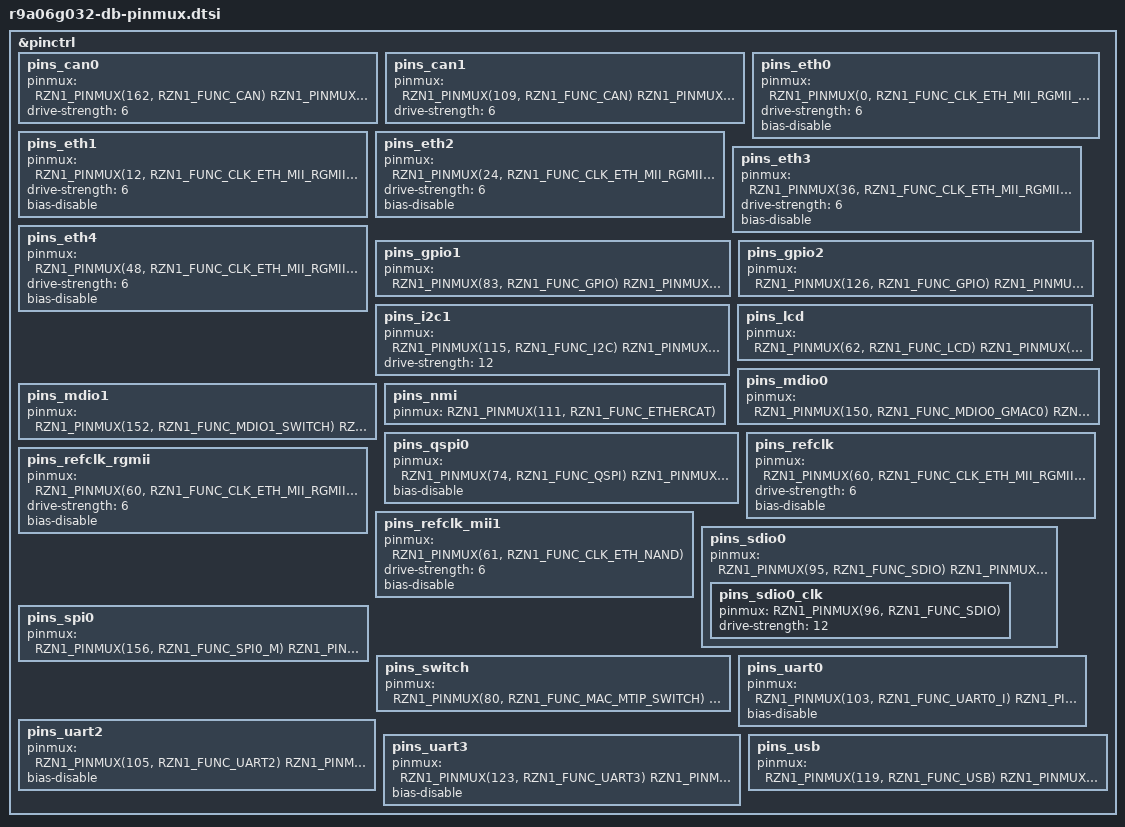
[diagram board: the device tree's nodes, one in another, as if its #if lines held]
/*
 * This file was autogenerated
 * DO NOT EDIT
 * (C) 2015-2022 Renesas Electronics Europe Ltd.
 * All rights reserved.
 *
 * Redistribution and use in source and binary forms, with or without
 * modification, are permitted provided that the following conditions are met:
 *
 * 1. Redistributions of source code must retain the above copyright notice,
 * this list of conditions and the following disclaimer.
 *
 * 2. Redistributions in binary form must reproduce the above copyright notice,
 * this list of conditions and the following disclaimer in the documentation
 * and/or other materials provided with the distribution.
 *
 * THIS SOFTWARE IS PROVIDED BY THE COPYRIGHT HOLDERS AND CONTRIBUTORS "AS IS"
 * AND ANY EXPRESS OR IMPLIED WARRANTIES, INCLUDING, BUT NOT LIMITED TO, THE
 * IMPLIED WARRANTIES OF MERCHANTABILITY AND FITNESS FOR A PARTICULAR PURPOSE
 * ARE DISCLAIMED. IN NO EVENT SHALL THE COPYRIGHT HOLDER OR CONTRIBUTORS BE
 * LIABLE FOR ANY DIRECT, INDIRECT, INCIDENTAL, SPECIAL, EXEMPLARY, OR
 * CONSEQUENTIAL DAMAGES (INCLUDING, BUT NOT LIMITED TO, PROCUREMENT OF
 * SUBSTITUTE GOODS OR SERVICES; LOSS OF USE, DATA, OR PROFITS; OR BUSINESS
 * INTERRUPTION) HOWEVER CAUSED AND ON ANY THEORY OF LIABILITY, WHETHER IN
 * CONTRACT, STRICT LIABILITY, OR TORT (INCLUDING NEGLIGENCE OR OTHERWISE)
 * ARISING IN ANY WAY OUT OF THE USE OF THIS SOFTWARE, EVEN IF ADVISED OF THE
 * POSSIBILITY OF SUCH DAMAGE.
 */

/*
 * AUTOGENERATED DO NOT EDIT
 *
 * Renesas RZ/N1D Demo Board
 * This file only sets the pin function by default.
 *
 * You can override the default mux pullup/down and drive by
 * defining the following macros in the board file before
 * including this.
 */

/*
 * Currently this does not support drive strength or pull
 */

#include <dt-bindings/pinctrl/rzn1-pinctrl.h>

&pinctrl {
	pins_can0: pins_can0 {
		pinmux = <
			RZN1_PINMUX(162, RZN1_FUNC_CAN)	/* CAN0_TXD */
			RZN1_PINMUX(163, RZN1_FUNC_CAN)	/* CAN0_RXD */
		>;
		drive-strength = <6>;
	};
	pins_can1: pins_can1 {
		pinmux = <
			RZN1_PINMUX(109, RZN1_FUNC_CAN)	/* CAN1_TXD */
			RZN1_PINMUX(110, RZN1_FUNC_CAN)	/* CAN1_RXD */
		>;
		drive-strength = <6>;
	};
	pins_eth0: pins_eth0 {
		pinmux = <
			RZN1_PINMUX(0, RZN1_FUNC_CLK_ETH_MII_RGMII_RMII)	/* ETH0_TXCLK */
			RZN1_PINMUX(1, RZN1_FUNC_CLK_ETH_MII_RGMII_RMII)	/* ETH0_TXD[0] */
			RZN1_PINMUX(2, RZN1_FUNC_CLK_ETH_MII_RGMII_RMII)	/* ETH0_TXD[1] */
			RZN1_PINMUX(3, RZN1_FUNC_CLK_ETH_MII_RGMII_RMII)	/* ETH0_TXD[2] */
			RZN1_PINMUX(4, RZN1_FUNC_CLK_ETH_MII_RGMII_RMII)	/* ETH0_TXD[3] */
			RZN1_PINMUX(5, RZN1_FUNC_CLK_ETH_MII_RGMII_RMII)	/* ETH0_TXEN */
			RZN1_PINMUX(6, RZN1_FUNC_CLK_ETH_MII_RGMII_RMII)	/* ETH0_RXCLK */
			RZN1_PINMUX(7, RZN1_FUNC_CLK_ETH_MII_RGMII_RMII)	/* ETH0_RXD[0] */
			RZN1_PINMUX(8, RZN1_FUNC_CLK_ETH_MII_RGMII_RMII)	/* ETH0_RXD[1] */
			RZN1_PINMUX(9, RZN1_FUNC_CLK_ETH_MII_RGMII_RMII)	/* ETH0_RXD[2] */
			RZN1_PINMUX(10, RZN1_FUNC_CLK_ETH_MII_RGMII_RMII)	/* ETH0_RXD[3] */
			RZN1_PINMUX(11, RZN1_FUNC_CLK_ETH_MII_RGMII_RMII)	/* ETH0_RXDV */
		>;
		drive-strength = <6>;
		bias-disable;
	};
	pins_eth1: pins_eth1 {
		pinmux = <
			RZN1_PINMUX(12, RZN1_FUNC_CLK_ETH_MII_RGMII_RMII)	/* ETH1_TXCLK */
			RZN1_PINMUX(13, RZN1_FUNC_CLK_ETH_MII_RGMII_RMII)	/* ETH1_TXD[0] */
			RZN1_PINMUX(14, RZN1_FUNC_CLK_ETH_MII_RGMII_RMII)	/* ETH1_TXD[1] */
			RZN1_PINMUX(15, RZN1_FUNC_CLK_ETH_MII_RGMII_RMII)	/* ETH1_TXD[2] */
			RZN1_PINMUX(16, RZN1_FUNC_CLK_ETH_MII_RGMII_RMII)	/* ETH1_TXD[3] */
			RZN1_PINMUX(17, RZN1_FUNC_CLK_ETH_MII_RGMII_RMII)	/* ETH1_TXEN */
			RZN1_PINMUX(18, RZN1_FUNC_CLK_ETH_MII_RGMII_RMII)	/* ETH1_RXCLK */
			RZN1_PINMUX(19, RZN1_FUNC_CLK_ETH_MII_RGMII_RMII)	/* ETH1_RXD[0] */
			RZN1_PINMUX(20, RZN1_FUNC_CLK_ETH_MII_RGMII_RMII)	/* ETH1_RXD[1] */
			RZN1_PINMUX(21, RZN1_FUNC_CLK_ETH_MII_RGMII_RMII)	/* ETH1_RXD[2] */
			RZN1_PINMUX(22, RZN1_FUNC_CLK_ETH_MII_RGMII_RMII)	/* ETH1_RXD[3] */
			RZN1_PINMUX(23, RZN1_FUNC_CLK_ETH_MII_RGMII_RMII)	/* ETH1_RXDV */
		>;
		drive-strength = <6>;
		bias-disable;
	};
	pins_eth2: pins_eth2 {
		pinmux = <
			RZN1_PINMUX(24, RZN1_FUNC_CLK_ETH_MII_RGMII_RMII)	/* ETH2_TXCLK */
			RZN1_PINMUX(25, RZN1_FUNC_CLK_ETH_MII_RGMII_RMII)	/* ETH2_TXD[0] */
			RZN1_PINMUX(26, RZN1_FUNC_CLK_ETH_MII_RGMII_RMII)	/* ETH2_TXD[1] */
			RZN1_PINMUX(27, RZN1_FUNC_CLK_ETH_MII_RGMII_RMII)	/* ETH2_TXD[2] */
			RZN1_PINMUX(28, RZN1_FUNC_CLK_ETH_MII_RGMII_RMII)	/* ETH2_TXD[3] */
			RZN1_PINMUX(29, RZN1_FUNC_CLK_ETH_MII_RGMII_RMII)	/* ETH2_TXEN */
			RZN1_PINMUX(30, RZN1_FUNC_CLK_ETH_MII_RGMII_RMII)	/* ETH2_RXCLK */
			RZN1_PINMUX(31, RZN1_FUNC_CLK_ETH_MII_RGMII_RMII)	/* ETH2_RXD[0] */
			RZN1_PINMUX(32, RZN1_FUNC_CLK_ETH_MII_RGMII_RMII)	/* ETH2_RXD[1] */
			RZN1_PINMUX(33, RZN1_FUNC_CLK_ETH_MII_RGMII_RMII)	/* ETH2_RXD[2] */
			RZN1_PINMUX(34, RZN1_FUNC_CLK_ETH_MII_RGMII_RMII)	/* ETH2_RXD[3] */
			RZN1_PINMUX(35, RZN1_FUNC_CLK_ETH_MII_RGMII_RMII)	/* ETH2_RXDV */
		>;
		drive-strength = <6>;
		bias-disable;
	};
	pins_eth3: pins_eth3 {
		pinmux = <
			RZN1_PINMUX(36, RZN1_FUNC_CLK_ETH_MII_RGMII_RMII)	/* ETH3_TXCLK */
			RZN1_PINMUX(37, RZN1_FUNC_CLK_ETH_MII_RGMII_RMII)	/* ETH3_TXD[0] */
			RZN1_PINMUX(38, RZN1_FUNC_CLK_ETH_MII_RGMII_RMII)	/* ETH3_TXD[1] */
			RZN1_PINMUX(39, RZN1_FUNC_CLK_ETH_MII_RGMII_RMII)	/* ETH3_TXD[2] */
			RZN1_PINMUX(40, RZN1_FUNC_CLK_ETH_MII_RGMII_RMII)	/* ETH3_TXD[3] */
			RZN1_PINMUX(41, RZN1_FUNC_CLK_ETH_MII_RGMII_RMII)	/* ETH3_TXEN */
			RZN1_PINMUX(42, RZN1_FUNC_CLK_ETH_MII_RGMII_RMII)	/* ETH3_RXCLK */
			RZN1_PINMUX(43, RZN1_FUNC_CLK_ETH_MII_RGMII_RMII)	/* ETH3_RXD[0] */
			RZN1_PINMUX(44, RZN1_FUNC_CLK_ETH_MII_RGMII_RMII)	/* ETH3_RXD[1] */
			RZN1_PINMUX(45, RZN1_FUNC_CLK_ETH_MII_RGMII_RMII)	/* ETH3_RXD[2] */
			RZN1_PINMUX(46, RZN1_FUNC_CLK_ETH_MII_RGMII_RMII)	/* ETH3_RXD[3] */
			RZN1_PINMUX(47, RZN1_FUNC_CLK_ETH_MII_RGMII_RMII)	/* ETH3_RXDV */
		>;
		drive-strength = <6>;
		bias-disable;
	};
	pins_eth4: pins_eth4 {
		pinmux = <
			RZN1_PINMUX(48, RZN1_FUNC_CLK_ETH_MII_RGMII_RMII)	/* ETH4_TXCLK */
			RZN1_PINMUX(49, RZN1_FUNC_CLK_ETH_MII_RGMII_RMII)	/* ETH4_TXD[0] */
			RZN1_PINMUX(50, RZN1_FUNC_CLK_ETH_MII_RGMII_RMII)	/* ETH4_TXD[1] */
			RZN1_PINMUX(51, RZN1_FUNC_CLK_ETH_MII_RGMII_RMII)	/* ETH4_TXD[2] */
			RZN1_PINMUX(52, RZN1_FUNC_CLK_ETH_MII_RGMII_RMII)	/* ETH4_TXD[3] */
			RZN1_PINMUX(53, RZN1_FUNC_CLK_ETH_MII_RGMII_RMII)	/* ETH4_TXEN */
			RZN1_PINMUX(54, RZN1_FUNC_CLK_ETH_MII_RGMII_RMII)	/* ETH4_RXCLK */
			RZN1_PINMUX(55, RZN1_FUNC_CLK_ETH_MII_RGMII_RMII)	/* ETH4_RXD[0] */
			RZN1_PINMUX(56, RZN1_FUNC_CLK_ETH_MII_RGMII_RMII)	/* ETH4_RXD[1] */
			RZN1_PINMUX(57, RZN1_FUNC_CLK_ETH_MII_RGMII_RMII)	/* ETH4_RXD[2] */
			RZN1_PINMUX(58, RZN1_FUNC_CLK_ETH_MII_RGMII_RMII)	/* ETH4_RXD[3] */
			RZN1_PINMUX(59, RZN1_FUNC_CLK_ETH_MII_RGMII_RMII)	/* ETH4_RXDV */
		>;
		drive-strength = <6>;
		bias-disable;
	};
	pins_gpio1: pins_gpio1 {
		pinmux = <
			RZN1_PINMUX(83, RZN1_FUNC_GPIO)	/* GPIO1B[14] */
			RZN1_PINMUX(84, RZN1_FUNC_GPIO)	/* GPIO1B[15] */
			RZN1_PINMUX(85, RZN1_FUNC_GPIO)	/* GPIO1B[16] */
			RZN1_PINMUX(86, RZN1_FUNC_GPIO)	/* GPIO1B[17] */
			RZN1_PINMUX(87, RZN1_FUNC_GPIO)	/* GPIO1B[18] */
			RZN1_PINMUX(88, RZN1_FUNC_GPIO)	/* GPIO1B[19] */
			RZN1_PINMUX(89, RZN1_FUNC_GPIO)	/* GPIO1B[20] */
			RZN1_PINMUX(90, RZN1_FUNC_GPIO)	/* GPIO1B[21] */
			RZN1_PINMUX(91, RZN1_FUNC_GPIO)	/* GPIO1B[22] */
			RZN1_PINMUX(92, RZN1_FUNC_GPIO)	/* GPIO1B[23] */
			RZN1_PINMUX(93, RZN1_FUNC_GPIO)	/* GPIO1B[24] */
			RZN1_PINMUX(94, RZN1_FUNC_GPIO)	/* Eth PHY Reset (GPIO1B[25]) */
			RZN1_PINMUX(117, RZN1_FUNC_GPIO)	/* GPIO1A[27] */
			RZN1_PINMUX(118, RZN1_FUNC_GPIO)	/* Eth3 IRQ (GPIO1A[28]) */
			RZN1_PINMUX(154, RZN1_FUNC_GPIO)	/* MDC PHY1 GPIO (GPIO1B[30]) */
			RZN1_PINMUX(155, RZN1_FUNC_GPIO)	/* MDIO PHY1 GPIO (GPIO1B[31]) */
		>;
	};
	pins_gpio2: pins_gpio2 {
		pinmux = <
			RZN1_PINMUX(126, RZN1_FUNC_GPIO)	/* Eth2 IRQ (GPIO2A[4]) */
			RZN1_PINMUX(146, RZN1_FUNC_GPIO)	/* Eth1 IRQ (GPIO2A[24]) */
			RZN1_PINMUX(147, RZN1_FUNC_GPIO)	/* Eth4 IRQ (GPIO2A[25]) */
			RZN1_PINMUX(148, RZN1_FUNC_GPIO)	/* Touch IRQ (GPIO2A[26]) */
			RZN1_PINMUX(149, RZN1_FUNC_GPIO)	/* Eth5 IRQ (GPIO2A[27]) */
			RZN1_PINMUX(159, RZN1_FUNC_GPIO)	/* SPI CS (GPIO2A[31]) */
		>;
	};
	pins_i2c1: pins_i2c1 {
		pinmux = <
			RZN1_PINMUX(115, RZN1_FUNC_I2C)	/* I2C1_SCL */
			RZN1_PINMUX(116, RZN1_FUNC_I2C)	/* I2C1_SDA */
		>;
		drive-strength = <12>;
	};
	pins_lcd: pins_lcd {
		pinmux = <
			RZN1_PINMUX(62, RZN1_FUNC_LCD)	/* LCD_R[1] */
			RZN1_PINMUX(63, RZN1_FUNC_LCD)	/* LCD_G[1] */
			RZN1_PINMUX(64, RZN1_FUNC_LCD)	/* LCD_B[1] */
			RZN1_PINMUX(65, RZN1_FUNC_LCD)	/* LCD_R[2] */
			RZN1_PINMUX(66, RZN1_FUNC_LCD)	/* LCD_G[2] */
			RZN1_PINMUX(67, RZN1_FUNC_LCD)	/* LCD_B[2] */
			RZN1_PINMUX(68, RZN1_FUNC_LCD)	/* LCD_R[3] */
			RZN1_PINMUX(69, RZN1_FUNC_LCD)	/* LCD_G[3] */
			RZN1_PINMUX(70, RZN1_FUNC_LCD)	/* LCD_B[3] */
			RZN1_PINMUX(71, RZN1_FUNC_LCD)	/* LCD_R[4] */
			RZN1_PINMUX(72, RZN1_FUNC_LCD)	/* LCD_G[4] */
			RZN1_PINMUX(73, RZN1_FUNC_LCD)	/* LCD_B[4] */
			RZN1_PINMUX(127, RZN1_FUNC_LCD)	/* LCD_PWM[0] */
			RZN1_PINMUX(128, RZN1_FUNC_LCD)	/* LCD_PCLK */
			RZN1_PINMUX(129, RZN1_FUNC_LCD)	/* LCD_HSYNC */
			RZN1_PINMUX(130, RZN1_FUNC_LCD)	/* LCD_VSYNC */
			RZN1_PINMUX(131, RZN1_FUNC_LCD)	/* LCD_DE */
			RZN1_PINMUX(132, RZN1_FUNC_LCD)	/* LCD_PE */
			RZN1_PINMUX(133, RZN1_FUNC_LCD)	/* LCD_PWM[1] */
			RZN1_PINMUX(134, RZN1_FUNC_LCD)	/* LCD_R[5] */
			RZN1_PINMUX(135, RZN1_FUNC_LCD)	/* LCD_R[0] */
			RZN1_PINMUX(136, RZN1_FUNC_LCD)	/* LCD_G[0] */
			RZN1_PINMUX(137, RZN1_FUNC_LCD)	/* LCD_B[0] */
			RZN1_PINMUX(138, RZN1_FUNC_LCD)	/* LCD_R[6] */
			RZN1_PINMUX(139, RZN1_FUNC_LCD)	/* LCD_G[6] */
			RZN1_PINMUX(140, RZN1_FUNC_LCD)	/* LCD_B[6] */
			RZN1_PINMUX(141, RZN1_FUNC_LCD)	/* LCD_R[7] */
			RZN1_PINMUX(142, RZN1_FUNC_LCD)	/* LCD_G[7] */
			RZN1_PINMUX(143, RZN1_FUNC_LCD)	/* LCD_B[7] */
			RZN1_PINMUX(144, RZN1_FUNC_LCD)	/* LCD_G[5] */
			RZN1_PINMUX(145, RZN1_FUNC_LCD)	/* LCD_B[5] */
		>;
	};
	pins_mdio0: pins_mdio0 {
		pinmux = <
			RZN1_PINMUX(150, RZN1_FUNC_MDIO0_GMAC0)	/* MDIO0_MDC */
			RZN1_PINMUX(151, RZN1_FUNC_MDIO0_GMAC0)	/* MDIO0_MDIO */
		>;
	};
	pins_mdio1: pins_mdio1 {
		pinmux = <
			RZN1_PINMUX(152, RZN1_FUNC_MDIO1_SWITCH)	/* MDIO1_MDC */
			RZN1_PINMUX(153, RZN1_FUNC_MDIO1_SWITCH)	/* MDIO1_MDIO */
		>;
	};
	pins_nmi: pins_nmi {
		pinmux = <
			RZN1_PINMUX(111, RZN1_FUNC_ETHERCAT)	/* NMI_CORTEXM3 */
		>;
	};
	pins_qspi0: pins_qspi0 {
		pinmux = <
			RZN1_PINMUX(74, RZN1_FUNC_QSPI)	/* QSPI0_CS_N[0] */
			RZN1_PINMUX(75, RZN1_FUNC_QSPI)	/* QSPI0_IO[3] */
			RZN1_PINMUX(76, RZN1_FUNC_QSPI)	/* QSPI0_IO[2] */
			RZN1_PINMUX(77, RZN1_FUNC_QSPI)	/* QSPI0_IO[1] */
			RZN1_PINMUX(78, RZN1_FUNC_QSPI)	/* QSPI0_IO[0] */
			RZN1_PINMUX(79, RZN1_FUNC_QSPI)	/* QSPI0_CLK */
		>;
		bias-disable;
	};
	pins_refclk: pins_refclk {
		pinmux = <
			RZN1_PINMUX(60, RZN1_FUNC_CLK_ETH_MII_RGMII_RMII)	/* REFCLK_RGMII */
			RZN1_PINMUX(61, RZN1_FUNC_CLK_ETH_NAND)	/* REFCLK_MII[1] */
		>;
		drive-strength = <6>;
		bias-disable;
	};
	pins_refclk_rgmii: pins_refclk_rgmii {
		pinmux = <
			RZN1_PINMUX(60, RZN1_FUNC_CLK_ETH_MII_RGMII_RMII)	/* REFCLK_RGMII */
		>;
		drive-strength = <6>;
		bias-disable;
	};
	pins_refclk_mii1: pins_refclk_mii1 {
		pinmux = <
			RZN1_PINMUX(61, RZN1_FUNC_CLK_ETH_NAND)	/* REFCLK_MII[1] */
		>;
		drive-strength = <6>;
		bias-disable;
	};
	pins_sdio0: pins_sdio0 {
		pinmux = <
			RZN1_PINMUX(95, RZN1_FUNC_SDIO)	/* SDIO0_CMD */
			RZN1_PINMUX(97, RZN1_FUNC_SDIO)	/* SDIO0_IO[0] */
			RZN1_PINMUX(98, RZN1_FUNC_SDIO)	/* SDIO0_IO[1] */
			RZN1_PINMUX(99, RZN1_FUNC_SDIO)	/* SDIO0_IO[2] */
			RZN1_PINMUX(100, RZN1_FUNC_SDIO)	/* SDIO0_IO[3] */
			RZN1_PINMUX(101, RZN1_FUNC_SDIO_E)	/* SDIO0_CD_N */
			RZN1_PINMUX(102, RZN1_FUNC_SDIO_E)	/* SDIO0_WP */
		>;
		pins_sdio0_clk {
			pinmux = <
				RZN1_PINMUX(96, RZN1_FUNC_SDIO)		/* SDIO0_CLK */
			>;
			drive-strength = <12>;
		};
	};
	pins_spi0: pins_spi0 {
		pinmux = <
			RZN1_PINMUX(156, RZN1_FUNC_SPI0_M)	/* SPI0_CLK */
			RZN1_PINMUX(157, RZN1_FUNC_SPI0_M)	/* SPI0_MOSI */
			RZN1_PINMUX(158, RZN1_FUNC_SPI0_M)	/* SPI0_MISO */
		>;
	};
	pins_switch: pins_switch {
		pinmux = <
			RZN1_PINMUX(80, RZN1_FUNC_MAC_MTIP_SWITCH)	/* SWITCH_MII_LINK[5] */
			RZN1_PINMUX(81, RZN1_FUNC_MAC_MTIP_SWITCH)	/* SWITCH_MII_LINK[4] */
			RZN1_PINMUX(82, RZN1_FUNC_MAC_MTIP_SWITCH)	/* SWITCH_MII_LINK[3] */
			RZN1_PINMUX(114, RZN1_FUNC_MAC_MTIP_SWITCH)	/* SWITCH_MII_LINK[2] */
		>;
	};
	pins_uart0: pins_uart0 {
		pinmux = <
			RZN1_PINMUX(103, RZN1_FUNC_UART0_I)	/* UART0_TXD */
			RZN1_PINMUX(104, RZN1_FUNC_UART0_I)	/* UART0_RXD */
		>;
		bias-disable;
	};
	pins_uart2: pins_uart2 {
		pinmux = <
			RZN1_PINMUX(105, RZN1_FUNC_UART2)	/* UART2_TXD */
			RZN1_PINMUX(106, RZN1_FUNC_UART2)	/* UART2_RXD */
			RZN1_PINMUX(107, RZN1_FUNC_UART2)	/* UART2_RTS_N */
			RZN1_PINMUX(108, RZN1_FUNC_UART2)	/* UART2_CTS_N */
		>;
		bias-disable;
	};
	pins_uart3: pins_uart3 {
		pinmux = <
			RZN1_PINMUX(123, RZN1_FUNC_UART3)	/* UART3_TXD */
			RZN1_PINMUX(124, RZN1_FUNC_UART3)	/* UART3_RXD */
			RZN1_PINMUX(125, RZN1_FUNC_UART3)	/* UART3_RTS_N */
		>;
		bias-disable;
	};
	pins_usb: pins_usb {
		pinmux = <
			RZN1_PINMUX(119, RZN1_FUNC_USB)	/* USB_PPON1 */
			RZN1_PINMUX(120, RZN1_FUNC_USB)	/* USB_OC1 */
			RZN1_PINMUX(121, RZN1_FUNC_USB)	/* USB_PPON2 */
			RZN1_PINMUX(122, RZN1_FUNC_USB)	/* USB_OC2 */
		>;
	};
};

/*
 * This is the compressed Renesas Pinmux Web App data structure; this is
 * used to allow uploading this file back into the web app, make some
 * more changes and generate/save the DTS again. It is not used by Linux
 * in any way.
 */
#ifdef JSON_PRESET
N4IgdghgtgpiBcIBKMwwM4XQAiQLQHoA5ARgBFsyYoB7bAIRogCcATEAGhAAcIBjANYQA5nEQwALAAYpnHjGYBLbgAsFEADboEAb
RABhAIKk5RogCY5AUQAqACRLX7lrrbsBmJ3YleArHIBxAAUASQB5FxBg8M8uEPN9SIAZfTI5AFkycMcuTPDIonSQuQBFAGVQnOQr
ADF9JIBpOTKssKqKkPaAdRCbfTs5AFVDJBsq4dHYkAmbHy5BsvohxfHFywBdLmFuRRoAfUhYbXhQAE5LRCsAFxV3bBCkErkSc0dL
m+wguwBNXAwYK7PcwANgQIEy+k+PxI2GiYSBAHYwXkwlDvjC4c93BcQNcVOZ7o9nr4cXiYQ8nlwSL5PO8VBJCZSQNSfIgbDQAK58
FSM4n+Om+XlU3ynMEdbD6MogAC+Wx2NGOOgRvgkJARwI4ytVCIRmpVaoAHHrtadjSQDVIzQaSFbzFb3FaJFbfFaNVrzbr3QajV7T
e7Tpb/Tb/Xb/Q7/U7/S7/W79adPXGfXG/SrzDJjWng6mpKHs+Hs5Hs9Hs7GJGmE2WpEnKymyyRA6mSFm67m6/m64W68W66XXhXXt
XXrXzGmM68x62R+2R52R92R73zP3zIPzMP3A2y+5m+ZsRn3NP3LP3C7fL51SuOGeEd6XUf3MCNffgbrn0bn6b7wjLV+bV+7V+Dpf
k6X53hI7jqhwX66me1oqlevhwaeiHUhqsHUjBKGIQhcGmr49bmE6+E5qeBEahI6qnKaFHfpaNFSDa9F2vRDr0U69EuvR5E6lIur0
Ua9HUTq9ZQaq4EcBI5wGqcT5iWBJASLJCmvmJ77AiQ8ZQeppxGr4wJLqcNp6QZdp6TSNJXsC5lEVZJ6nrZekcIREiIaazkij+emn
HeXlPl5MH1thvhSMCVGniFVHcQiB4STqR5aTpQGhQaIHJXeyXkdS3kSVlmUinxOplqJ4F/hI4EAWVMVHuBIGVWB4GyeBKnge+lWf
mV0jFaqXUVZVXW1WV9WKV1zUSK1ZVCResXqqxOrAuxc3pcFAFWVISXBalwWcTq37TQijGqt6EmHdRqoBntLrOfNdpXeJ+H6WhJJN
us0pAA==
#endif
